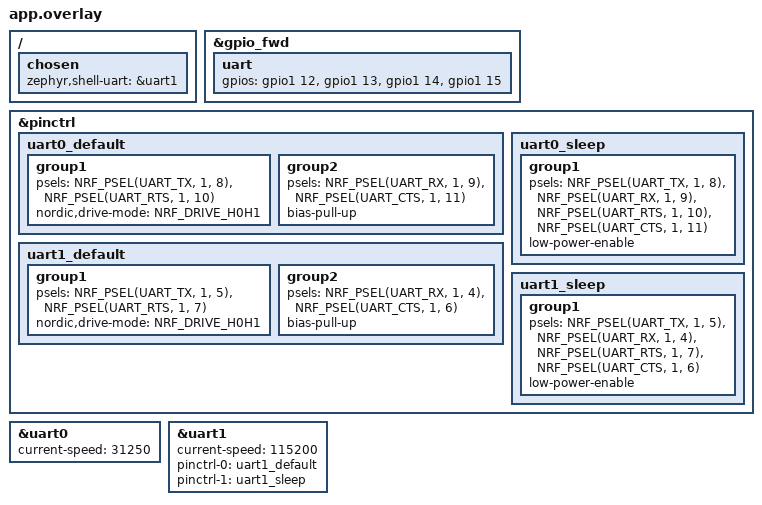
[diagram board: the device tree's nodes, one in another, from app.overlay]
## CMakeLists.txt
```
# SPDX-License-Identifier: Apache-2.0

cmake_minimum_required(VERSION 3.20.0)

# ============================================================================
# Firmware Version Configuration
# ============================================================================
# Update FIRMWARE_VERSION_MINOR for each build/change to track versions
set(FIRMWARE_VERSION_MAJOR 1)
set(FIRMWARE_VERSION_MINOR 3)
set(FIRMWARE_VERSION_PATCH 1)
set(FIRMWARE_VERSION "${FIRMWARE_VERSION_MAJOR}.${FIRMWARE_VERSION_MINOR}.${FIRMWARE_VERSION_PATCH}")

# Force use of nRF SDK Python - check multiple sources
if(DEFINED WEST_PYTHON)
  set(Python3_EXECUTABLE "${WEST_PYTHON}" CACHE FILEPATH "Python executable" FORCE)
elseif(DEFINED ENV{WEST_PYTHON})
  set(Python3_EXECUTABLE "$ENV{WEST_PYTHON}" CACHE FILEPATH "Python executable" FORCE)
elseif(EXISTS "/opt/nordic/ncs/toolchains/322ac893fe/opt/python@3.12/bin/python3.12")
  # Fallback to known SDK Python location
  set(Python3_EXECUTABLE "/opt/nordic/ncs/toolchains/322ac893fe/opt/python@3.12/bin/python3.12" CACHE FILEPATH "Python executable" FORCE)
endif()

find_package(Zephyr REQUIRED HINTS $ENV{ZEPHYR_BASE})
project(guitaracc_basestation)

# ============================================================================
# Generate version header file
# ============================================================================
set(VERSION_HEADER_DIR "${CMAKE_CURRENT_BINARY_DIR}/include")
set(VERSION_HEADER "${VERSION_HEADER_DIR}/firmware_version.h")

# Create include directory
file(MAKE_DIRECTORY "${VERSION_HEADER_DIR}")

# Generate version header
configure_file(
    "${CMAKE_CURRENT_SOURCE_DIR}/src/firmware_version.h.in"
    "${VERSION_HEADER}"
    @ONLY
)

# Add generated include directory to build
target_include_directories(app PRIVATE "${VERSION_HEADER_DIR}")

# Display version during build
message(STATUS "GuitarAcc Basestation Firmware Version: ${FIRMWARE_VERSION}")

# ============================================================================
# Source files
# ============================================================================
target_sources(app PRIVATE 
    src/main.c
    src/midi_logic.c
    src/accel_mapping.c
    src/ui_led.c
    src/ui_interface_shell.c
    src/config_storage.c
)
```

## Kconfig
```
# Copyright (c) 2026 GuitarAcc Project
# SPDX-License-Identifier: Apache-2.0

menu "GuitarAcc Configuration"

config CONFIG_ALLOW_DEFAULT_WRITE
	bool "Allow writing to factory DEFAULT configuration area"
	default n
	help
	  Enable this option to allow writing factory default configuration
	  to the DEFAULT area in QSPI flash. This should only be enabled
	  during development and manufacturing setup.
	  
	  WARNING: This must be disabled for production builds to prevent
	  accidental overwrite of factory defaults.

endmenu

source "Kconfig.zephyr"
```

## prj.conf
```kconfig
# Bluetooth configuration
CONFIG_BT=y
CONFIG_BT_CENTRAL=y
CONFIG_BT_DEVICE_NAME="GuitarAcc Base"
CONFIG_BT_MAX_CONN=4
CONFIG_BT_MAX_PAIRED=4
CONFIG_BT_GATT_CLIENT=y
CONFIG_BT_SMP=y
CONFIG_BT_GATT_DM=y
CONFIG_BT_HOGP=y

# Scan library configuration
CONFIG_BT_SCAN=y
CONFIG_BT_SCAN_FILTER_ENABLE=y
CONFIG_BT_SCAN_UUID_CNT=1

# Settings for bonding
CONFIG_BT_SETTINGS=y
CONFIG_FLASH=y
CONFIG_FLASH_PAGE_LAYOUT=y
CONFIG_FLASH_MAP=y
CONFIG_SETTINGS=y
CONFIG_SETTINGS_NVS=y
CONFIG_NVS=y
CONFIG_NVS_LOG_LEVEL_DBG=y

# Flash driver for configuration storage
CONFIG_MPU_ALLOW_FLASH_WRITE=y

# Crypto for hash validation (using PSA Crypto API for nRF Connect SDK)
CONFIG_NRF_SECURITY=y
CONFIG_NORDIC_SECURITY_BACKEND=y
CONFIG_PSA_CRYPTO_DRIVER_OBERON=y
CONFIG_MBEDTLS_PSA_CRYPTO_C=y
CONFIG_MBEDTLS_SHA256_C=y
CONFIG_PSA_WANT_ALG_SHA_256=y

# Configuration storage options
# Enable this to allow writing factory defaults during development
# WARNING: Disable for production builds!
CONFIG_CONFIG_ALLOW_DEFAULT_WRITE=y

CONFIG_DK_LIBRARY=y
# Stack sizes
CONFIG_MAIN_STACK_SIZE=4096
CONFIG_SYSTEM_WORKQUEUE_STACK_SIZE=2048
CONFIG_HEAP_MEM_POOL_SIZE=2048

# UART for MIDI output
CONFIG_SERIAL=y
CONFIG_UART_INTERRUPT_DRIVEN=y
CONFIG_UART_LINE_CTRL=y

# GPIO for RGB LED control
CONFIG_GPIO=y

# Logging - RTT only, not on console/UART
CONFIG_LOG=y
CONFIG_LOG_PRINTK=n

# Shell (command line interface)
CONFIG_SHELL=y
CONFIG_SHELL_BACKEND_SERIAL=y
CONFIG_SHELL_PROMPT_UART="GuitarAcc:~$ "
CONFIG_SHELL_CMD_BUFF_SIZE=256
CONFIG_SHELL_PRINTF_BUFF_SIZE=512
CONFIG_SHELL_HISTORY=y
CONFIG_SHELL_HISTORY_BUFFER=512
CONFIG_SHELL_TAB=y
CONFIG_SHELL_TAB_AUTOCOMPLETION=y
CONFIG_SHELL_VT100_COLORS=y
CONFIG_SHELL_METAKEYS=y
CONFIG_SHELL_LOG_BACKEND=n

# Enable floating-point printf support for shell
CONFIG_CBPRINTF_FP_SUPPORT=y

# JSON support for config import/export
CONFIG_JSON_LIBRARY=y

# Console backend for shell only (no logging)
CONFIG_CONSOLE=y
CONFIG_UART_CONSOLE=y
CONFIG_CONSOLE_HANDLER=n

CONFIG_DEBUG_THREAD_INFO=y

# RTT (SEGGER Real-Time Transfer) for debug logging only
# RTT is used for ALL logging, UART is ONLY for shell
# TODO: Disable RTT before production shipment for performance/security
CONFIG_USE_SEGGER_RTT=y
CONFIG_RTT_CONSOLE=n
CONFIG_LOG_BACKEND_RTT=y
CONFIG_LOG_BACKEND_UART=n
CONFIG_LOG_BACKEND_SHOW_COLOR=n
CONFIG_LOG_BACKEND_FORMAT_TIMESTAMP=y
```

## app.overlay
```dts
/* UART configuration for MIDI output */

/* Chosen devices */
/ {
	chosen {
		zephyr,shell-uart = &uart1;
	};
};

/* Reconfigure GPIO forwarder to forward P1.12, P1.13, P1.14, P1.15 to network core */
&gpio_fwd {
	status = "okay";
	uart {
		gpios = <&gpio1 12 0>, <&gpio1 13 0>, <&gpio1 14 0>, <&gpio1 15 0>;
	};
};

/* Override UART0 pinctrl - TX and RX swapped: TX=P1.8, RX=P1.9, RTS=P1.10, CTS=P1.11 */
&pinctrl {
	uart0_default: uart0_default {
		group1 {
			psels = <NRF_PSEL(UART_TX, 1, 8)>,
				<NRF_PSEL(UART_RTS, 1, 10)>;
			nordic,drive-mode = <NRF_DRIVE_H0H1>;  /* High drive both LOW and HIGH (~5mA) */
		};
		group2 {
			psels = <NRF_PSEL(UART_RX, 1, 9)>,
				<NRF_PSEL(UART_CTS, 1, 11)>;
			bias-pull-up;
		};
	};

	uart0_sleep: uart0_sleep {
		group1 {
			psels = <NRF_PSEL(UART_TX, 1, 8)>,
				<NRF_PSEL(UART_RX, 1, 9)>,
				<NRF_PSEL(UART_RTS, 1, 10)>,
				<NRF_PSEL(UART_CTS, 1, 11)>;
			low-power-enable;
		};
	};
};

&uart0 {
	status = "okay";
	current-speed = <31250>;  /* MIDI baud rate */
};

/* Enable UART1 on VCOM0 pins for UI/Config interface */
&pinctrl {
	uart1_default: uart1_default {
		group1 {
			psels = <NRF_PSEL(UART_TX, 1, 5)>,
				<NRF_PSEL(UART_RTS, 1, 7)>;
			nordic,drive-mode = <NRF_DRIVE_H0H1>;
		};
		group2 {
			psels = <NRF_PSEL(UART_RX, 1, 4)>,
				<NRF_PSEL(UART_CTS, 1, 6)>;
			bias-pull-up;
		};
	};

	uart1_sleep: uart1_sleep {
		group1 {
			psels = <NRF_PSEL(UART_TX, 1, 5)>,
				<NRF_PSEL(UART_RX, 1, 4)>,
				<NRF_PSEL(UART_RTS, 1, 7)>,
				<NRF_PSEL(UART_CTS, 1, 6)>;
			low-power-enable;
		};
	};
};

&uart1 {
	status = "okay";
	current-speed = <115200>;  /* Standard VCOM baud rate */
	pinctrl-0 = <&uart1_default>;
	pinctrl-1 = <&uart1_sleep>;
	pinctrl-names = "default", "sleep";
};
```

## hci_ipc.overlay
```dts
/* Network core UART0 configuration - swapped to use P1.5, P1.4, P1.7, P1.6 */

&pinctrl {
	uart0_default: uart0_default {
		group1 {
			psels = <NRF_PSEL(UART_TX, 1, 5)>,
				<NRF_PSEL(UART_RTS, 1, 7)>;
		};
		group2 {
			psels = <NRF_PSEL(UART_RX, 1, 4)>,
				<NRF_PSEL(UART_CTS, 1, 6)>;
			bias-pull-up;
		};
	};

	uart0_sleep: uart0_sleep {
		group1 {
			psels = <NRF_PSEL(UART_TX, 1, 5)>,
				<NRF_PSEL(UART_RX, 1, 4)>,
				<NRF_PSEL(UART_RTS, 1, 7)>,
				<NRF_PSEL(UART_CTS, 1, 6)>;
			low-power-enable;
		};
	};
};
```

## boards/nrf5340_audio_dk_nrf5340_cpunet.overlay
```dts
/* Network core UART0 configuration - using P1.12-P1.15 */

&pinctrl {
	uart0_default: uart0_default {
		group1 {
			psels = <NRF_PSEL(UART_TX, 1, 12)>,
				<NRF_PSEL(UART_RTS, 1, 14)>;
		};
		group2 {
			psels = <NRF_PSEL(UART_RX, 1, 13)>,
				<NRF_PSEL(UART_CTS, 1, 15)>;
			bias-pull-up;
		};
	};

	uart0_sleep: uart0_sleep {
		group1 {
			psels = <NRF_PSEL(UART_TX, 1, 12)>,
				<NRF_PSEL(UART_RX, 1, 13)>,
				<NRF_PSEL(UART_RTS, 1, 14)>,
				<NRF_PSEL(UART_CTS, 1, 15)>;
			low-power-enable;
		};
	};
};
```

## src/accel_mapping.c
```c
/*
 * Accelerometer Rotation Pipeline
 * 3D rotation, normalization, and configurable conversion to MIDI
 * 
 * Copyright (c) 2026 GuitarAcc Project
 * SPDX-License-Identifier: Apache-2.0
 */

#include "accel_mapping.h"
#include <stddef.h>
#include <string.h>

#ifndef M_PI
#define M_PI 3.14159265358979323846
#endif

/* Fixed input points for lookup table interpolation */
static const float lookup_input_points[LOOKUP_TABLE_POINTS] = {
	-1.0f, -0.5f, 0.0f, 0.5f, 1.0f
};

/* Helper to clamp float to range */
static inline float clampf(float value, float min, float max)
{
	if (value < min) return min;
	if (value > max) return max;
	return value;
}

/* Helper to clamp to MIDI range */
static inline uint8_t clamp_midi(int32_t value)
{
	if (value < MIDI_MIN_VALUE) return MIDI_MIN_VALUE;
	if (value > MIDI_MAX_VALUE) return MIDI_MAX_VALUE;
	return (uint8_t)value;
}

/* Convert degrees to radians */
static inline float deg_to_rad(float degrees)
{
	return degrees * M_PI / 180.0f;
}

void accel_rotation_init_defaults(struct accel_rotation_config *config)
{
	if (config == NULL) {
		return;
	}
	
	memset(config, 0, sizeof(*config));
	config->rho_angle = 0.0f;
	config->theta_angle = 0.0f;
	config->midi_cc = 1;  /* Default to CC 1 (modulation wheel) */
	config->func_type = CONV_FUNC_LINEAR;
	config->params.linear.scale = 1.0f;
	config->params.linear.offset = 0.0f;
}

void apply_rotation(struct vector3d *vec, float rho_deg, float theta_deg)
{
	if (vec == NULL) {
		return;
	}
	
	float rho_rad = deg_to_rad(rho_deg);
	float theta_rad = deg_to_rad(theta_deg);
	
	float cos_rho = cosf(rho_rad);
	float sin_rho = sinf(rho_rad);
	float cos_theta = cosf(theta_rad);
	float sin_theta = sinf(theta_rad);
	
	/* Rotation around X axis (rho) */
	float y1 = vec->y * cos_rho - vec->z * sin_rho;
	float z1 = vec->y * sin_rho + vec->z * cos_rho;
	vec->y = y1;
	vec->z = z1;
	
	/* Rotation around Y axis (theta) */
	float x2 = vec->x * cos_theta + vec->z * sin_theta;
	float z2 = -vec->x * sin_theta + vec->z * cos_theta;
	vec->x = x2;
	vec->z = z2;
}

bool normalize_vector(struct vector3d *vec)
{
	if (vec == NULL) {
		return false;
	}
	
	float magnitude = sqrtf(vec->x * vec->x + vec->y * vec->y + vec->z * vec->z);
	
	/* Avoid division by zero */
	if (magnitude < 1e-6f) {
		return false;
	}
	
	vec->x /= magnitude;
	vec->y /= magnitude;
	vec->z /= magnitude;
	
	return true;
}

uint8_t scalar_to_midi(float scalar, enum conversion_func_type func_type,
                       const union conversion_params *params)
{
	if (params == NULL) {
		return MIDI_MIN_VALUE;
	}
	
	float result = 0.0f;
	
	/* Clamp input scalar to valid range */
	scalar = clampf(scalar, -1.0f, 1.0f);
	
	switch (func_type) {
	case CONV_FUNC_LINEAR: {
		/* Linear: MIDI = clamp((scalar * scale + offset) * 127, 0, 127) */
		result = (scalar * params->linear.scale + params->linear.offset) * 127.0f;
		break;
	}
	
	case CONV_FUNC_EXPONENTIAL: {
		/* Exponential: MIDI = clamp(((scalar + 1)/2)^exponent * 127, 0, 127) */
		float normalized = (scalar + 1.0f) / 2.0f;  /* Map to [0, 1] */
		result = powf(normalized, params->exponential.exponent) * 127.0f;
		break;
	}
	
	case CONV_FUNC_SCURVE: {
		/* S-Curve: MIDI = clamp(127 / (1 + e^(-steepness * scalar)), 0, 127) */
		float exp_val = expf(-params->scurve.steepness * scalar);
		result = 127.0f / (1.0f + exp_val);
		break;
	}
	
	case CONV_FUNC_LOOKUP: {
		/* Lookup table with linear interpolation */
		/* Find the two surrounding points */
		int idx = 0;
		for (int i = 0; i < LOOKUP_TABLE_POINTS - 1; i++) {
			if (scalar >= lookup_input_points[i] && scalar <= lookup_input_points[i + 1]) {
				idx = i;
				break;
			}
		}
		
		/* Handle edge case: scalar exactly at last point */
		if (scalar >= lookup_input_points[LOOKUP_TABLE_POINTS - 1]) {
			return params->lookup.values[LOOKUP_TABLE_POINTS - 1];
		}
		
		/* Linear interpolation between two points */
		float x0 = lookup_input_points[idx];
		float x1 = lookup_input_points[idx + 1];
		float y0 = (float)params->lookup.values[idx];
		float y1 = (float)params->lookup.values[idx + 1];
		
		float t = (scalar - x0) / (x1 - x0);
		result = y0 + t * (y1 - y0);
		break;
	}
	
	default:
		/* Unknown function type, return mid-range */
		return 64;
	}
	
	/* Clamp to MIDI range and return */
	return clamp_midi((int32_t)(result + 0.5f));  /* Round to nearest */
}

bool validate_rotation_config(struct accel_rotation_config *config)
{
	if (config == NULL) {
		return false;
	}
	
	bool valid = true;
	
	/* Validate angles (wrap to 0-360) */
	while (config->rho_angle < 0.0f) {
		config->rho_angle += 360.0f;
		valid = false;
	}
	while (config->rho_angle >= 360.0f) {
		config->rho_angle -= 360.0f;
		valid = false;
	}
	
	while (config->theta_angle < 0.0f) {
		config->theta_angle += 360.0f;
		valid = false;
	}
	while (config->theta_angle >= 360.0f) {
		config->theta_angle -= 360.0f;
		valid = false;
	}
	
	/* Validate MIDI CC (clamp to 0-127) */
	if (config->midi_cc > 127) {
		config->midi_cc = 127;
		valid = false;
	}
	
	/* Validate function type */
	if (config->func_type > CONV_FUNC_LOOKUP) {
		config->func_type = CONV_FUNC_LINEAR;
		valid = false;
	}
	
	/* Validate function parameters */
	switch (config->func_type) {
	case CONV_FUNC_LINEAR:
		/* Scale: -10.0 to -0.1 or 0.1 to 10.0 (exclude near-zero values) */
		if (config->params.linear.scale >= -0.1f && config->params.linear.scale <= 0.1f) {
			/* Too close to zero, snap to minimum magnitude */
			config->params.linear.scale = (config->params.linear.scale >= 0.0f) ? 0.1f : -0.1f;
			valid = false;
		} else if (config->params.linear.scale < -10.0f) {
			config->params.linear.scale = -10.0f;
			valid = false;
		} else if (config->params.linear.scale > 10.0f) {
			config->params.linear.scale = 10.0f;
			valid = false;
		}
		if (config->params.linear.offset < -1.0f || config->params.linear.offset > 1.0f) {
			config->params.linear.offset = clampf(config->params.linear.offset, -1.0f, 1.0f);
			valid = false;
		}
		break;
		
	case CONV_FUNC_EXPONENTIAL:
		if (config->params.exponential.exponent < 0.1f || 
		    config->params.exponential.exponent > 5.0f) {
			config->params.exponential.exponent = 
				clampf(config->params.exponential.exponent, 0.1f, 5.0f);
			valid = false;
		}
		break;
		
	case CONV_FUNC_SCURVE:
		if (config->params.scurve.steepness < 1.0f || 
		    config->params.scurve.steepness > 20.0f) {
			config->params.scurve.steepness = 
				clampf(config->params.scurve.steepness, 1.0f, 20.0f);
			valid = false;
		}
		break;
		
	case CONV_FUNC_LOOKUP:
		/* Validate all lookup table values are in MIDI range */
		for (int i = 0; i < LOOKUP_TABLE_POINTS; i++) {
			if (config->params.lookup.values[i] > 127) {
				config->params.lookup.values[i] = 127;
				valid = false;
			}
		}
		break;
	}
	
	return valid;
}

uint8_t accel_rotation_pipeline(const struct accel_rotation_config *config,
                                 int16_t accel_x, int16_t accel_y, int16_t accel_z,
                                 uint8_t *midi_cc_out)
{
	if (config == NULL) {
		if (midi_cc_out != NULL) {
			*midi_cc_out = 1;  /* Default CC */
		}
		return MIDI_MIN_VALUE;
	}
	
	/* Stage 1: Convert milli-g to g and create vector */
	struct vector3d vec = {
		.x = (float)accel_x / 1000.0f,
		.y = (float)accel_y / 1000.0f,
		.z = (float)accel_z / 1000.0f
	};
	
	/* Stage 2: Apply angular rotation */
	apply_rotation(&vec, config->rho_angle, config->theta_angle);
	
	/* Stage 3: Normalize to unit vector */
	if (!normalize_vector(&vec)) {
		/* If normalization fails (zero vector), return mid-range */
		if (midi_cc_out != NULL) {
			*midi_cc_out = config->midi_cc;
		}
		return 64;
	}
	
	/* Stage 4: Project to 1D (X-axis component) */
	float scalar = vec.x;  /* Already in range [-1.0, 1.0] after normalization */
	
	/* Stage 5: Convert scalar to MIDI */
	uint8_t midi_value = scalar_to_midi(scalar, config->func_type, &config->params);
	
	/* Output the MIDI CC number */
	if (midi_cc_out != NULL) {
		*midi_cc_out = config->midi_cc;
	}
	
	return midi_value;
}

/* =============================================================================
 * Legacy Compatibility Functions (deprecated)
 * ============================================================================= */

uint8_t accel_map_to_midi(const struct accel_mapping_config *config, int16_t accel_value)
{
	if (config == NULL) {
		return MIDI_MIN_VALUE;
	}
	
	/* Handle edge case where min == max to avoid division by zero */
	if (config->accel_min == config->accel_max) {
		return MIDI_MIN_VALUE;
	}
	
	/* Calculate the range */
	int32_t accel_range = (int32_t)config->accel_max - (int32_t)config->accel_min;
	int32_t accel_offset = (int32_t)accel_value - (int32_t)config->accel_min;
	
	/* Linear mapping with proper handling of positive and negative ranges */
	int32_t midi_value = (accel_offset * (MIDI_MAX_VALUE - MIDI_MIN_VALUE)) / accel_range;
	midi_value += MIDI_MIN_VALUE;
	
	/* Clamp to valid MIDI range */
	if (midi_value < MIDI_MIN_VALUE) {
		midi_value = MIDI_MIN_VALUE;
	} else if (midi_value > MIDI_MAX_VALUE) {
		midi_value = MIDI_MAX_VALUE;
	}
	
	return (uint8_t)midi_value;
}

void accel_mapping_init_linear(struct accel_mapping_config *config, 
                                int16_t accel_min, 
                                int16_t accel_max)
{
	if (config == NULL) {
		return;
	}
	
	config->accel_min = accel_min;
	config->accel_max = accel_max;
}
```

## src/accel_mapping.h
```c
/*
 * Accelerometer Rotation Pipeline
 * 3D rotation, normalization, and configurable conversion to MIDI
 * 
 * Copyright (c) 2026 GuitarAcc Project
 * SPDX-License-Identifier: Apache-2.0
 */

#ifndef ACCEL_MAPPING_H
#define ACCEL_MAPPING_H

#include <stdint.h>
#include <stdbool.h>
#include <math.h>

/* MIDI value range constants */
#define MIDI_MIN_VALUE 0
#define MIDI_MAX_VALUE 127

/* Number of lookup table points */
#define LOOKUP_TABLE_POINTS 5

/**
 * Conversion function types
 */
enum conversion_func_type {
	CONV_FUNC_LINEAR,      /* Linear scaling with offset */
	CONV_FUNC_EXPONENTIAL, /* Exponential curve */
	CONV_FUNC_SCURVE,      /* S-curve (sigmoid) */
	CONV_FUNC_LOOKUP       /* 5-point lookup table with linear interpolation */
};

/**
 * Conversion function parameters
 * Storage optimized for maximum 5 bytes per configuration
 */
union conversion_params {
	/* Linear: scale and offset */
	struct {
		float scale;   /* -10.0 to -0.1 or 0.1 to 10.0 (negative reverses direction) */
		float offset;  /* -1.0 to 1.0 */
	} linear;
	
	/* Exponential: single exponent parameter */
	struct {
		float exponent; /* 0.1 to 5.0 */
	} exponential;
	
	/* S-curve: steepness parameter */
	struct {
		float steepness; /* 1.0 to 20.0 */
	} scurve;
	
	/* Lookup table: 5 output values at fixed input points */
	struct {
		uint8_t values[LOOKUP_TABLE_POINTS]; /* Output MIDI values 0-127 */
		/* Fixed input points: -1.0, -0.5, 0.0, 0.5, 1.0 */
	} lookup;
};

/**
 * Accelerometer rotation pipeline configuration
 * Total storage: 15 bytes maximum
 */
struct accel_rotation_config {
	float rho_angle;     /* Rotation around X axis (degrees, 0-360) - 4 bytes */
	float theta_angle;   /* Rotation around Y axis (degrees, 0-360) - 4 bytes */
	uint8_t midi_cc;     /* MIDI CC number (0-127) - 1 byte */
	enum conversion_func_type func_type;  /* Conversion function type - 1 byte */
	union conversion_params params;       /* Function parameters - 5 bytes max */
};

/**
 * 3D vector for accelerometer data
 */
struct vector3d {
	float x;
	float y;
	float z;
};

/**
 * Initialize rotation pipeline configuration with defaults
 * Defaults: rho=0, theta=0, CC=1, linear function (scale=1.0, offset=0.0)
 * 
 * @param config Pointer to configuration structure to initialize
 */
void accel_rotation_init_defaults(struct accel_rotation_config *config);

/**
 * Process accelerometer data through rotation pipeline
 * 
 * Pipeline stages:
 * 1. Angular rotation (X and Y axis)
 * 2. Unit vector normalization
 * 3. 1D projection (X-axis)
 * 4. Scalar to MIDI conversion
 * 
 * @param config Pipeline configuration
 * @param accel_x X-axis acceleration (milli-g)
 * @param accel_y Y-axis acceleration (milli-g)
 * @param accel_z Z-axis acceleration (milli-g)
 * @param midi_cc_out Output MIDI CC number (from config)
 * @return MIDI value (0-127), clamped to valid range
 */
uint8_t accel_rotation_pipeline(const struct accel_rotation_config *config,
                                 int16_t accel_x, int16_t accel_y, int16_t accel_z,
                                 uint8_t *midi_cc_out);

/**
 * Apply angular rotation to 3D vector
 * Rotates around X axis (rho), then Y axis (theta)
 * 
 * @param vec Input/output vector
 * @param rho_deg Rotation around X axis (degrees)
 * @param theta_deg Rotation around Y axis (degrees)
 */
void apply_rotation(struct vector3d *vec, float rho_deg, float theta_deg);

/**
 * Normalize vector to unit length
 * 
 * @param vec Input/output vector
 * @return true if normalization successful, false if vector is zero
 */
bool normalize_vector(struct vector3d *vec);

/**
 * Convert scalar value to MIDI using configured conversion function
 * 
 * @param scalar Input scalar value (-1.0 to 1.0)
 * @param func_type Conversion function type
 * @param params Function parameters
 * @return MIDI value (0-127), clamped to valid range
 */
uint8_t scalar_to_midi(float scalar, enum conversion_func_type func_type,
                       const union conversion_params *params);

/**
 * Validate and sanitize pipeline configuration parameters
 * Invalid parameters are corrected to safe defaults
 * 
 * @param config Configuration to validate
 * @return true if configuration was valid, false if corrections were made
 */
bool validate_rotation_config(struct accel_rotation_config *config);

/* Legacy compatibility - deprecated, use rotation pipeline instead */
struct accel_mapping_config {
	int16_t accel_min;
	int16_t accel_max;
};
uint8_t accel_map_to_midi(const struct accel_mapping_config *config, int16_t accel_value);
void accel_mapping_init_linear(struct accel_mapping_config *config, 
                                int16_t accel_min, int16_t accel_max);

#endif /* ACCEL_MAPPING_H */
```

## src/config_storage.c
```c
/*
 * Copyright (c) 2026 GuitarAcc Project
 * SPDX-License-Identifier: Apache-2.0
 */

#include "config_storage.h"
#include <zephyr/kernel.h>
#include <zephyr/device.h>
#include <zephyr/drivers/flash.h>
#include <zephyr/logging/log.h>
#include <zephyr/sys/crc.h>
#include <string.h>

#if defined(CONFIG_MBEDTLS_SHA256_C)
#include <mbedtls/sha256.h>
#endif

LOG_MODULE_REGISTER(config_storage, LOG_LEVEL_DBG);

/* Magic number for configuration header */
#define CONFIG_MAGIC 0x47544143  /* "GTAC" */

/* Internal flash device (nRF5340 has 1MB internal flash) */
#define FLASH_DEVICE DEVICE_DT_GET(DT_CHOSEN(zephyr_flash_controller))

/* Memory layout in internal flash using Partition Manager
 * The settings_storage partition is 8KB at 0xFC000-0xFDFFF
 * This matches the partition manager output and avoids code conflicts
 */
#define CONFIG_FLASH_OFFSET  0x000FC000  /* From partition manager */
#define CONFIG_STORAGE_SIZE  0x00002000  /* 8KB (actual partition size) */

/* Ping-pong storage with two 4KB areas (no DEFAULT area) */
#define CONFIG_AREA_A_OFFSET   (CONFIG_FLASH_OFFSET + 0x0000)  /* +0KB */
#define CONFIG_AREA_A_SIZE     0x00001000  /* 4KB */
#define CONFIG_AREA_B_OFFSET   (CONFIG_FLASH_OFFSET + 0x1000)  /* +4KB */
#define CONFIG_AREA_B_SIZE     0x00001000  /* 4KB */

/* Flash page size for nRF5340 internal flash */
#define FLASH_PAGE_SIZE 4096

/* Current configuration state */
static struct config_data current_config;
static enum config_area active_area = CONFIG_AREA_A;
static uint32_t current_sequence = 0;
static bool initialized = false;

/* Runtime flag to enable DEFAULT area writes (double protection) */
static bool default_write_unlocked = false;

/* Flash device handle */
static const struct device *flash_dev;

/**
 * @brief Calculate SHA256 hash of data
 */
static int calculate_hash(const void *data, size_t len, uint8_t *hash)
{
#if defined(CONFIG_MBEDTLS_SHA256_C)
	mbedtls_sha256_context ctx;
	
	mbedtls_sha256_init(&ctx);
	int ret = mbedtls_sha256_starts(&ctx, 0); /* 0 = SHA256, not SHA224 */
	if (ret != 0) {
		mbedtls_sha256_free(&ctx);
		return -EIO;
	}
	
	ret = mbedtls_sha256_update(&ctx, data, len);
	if (ret != 0) {
		mbedtls_sha256_free(&ctx);
		return -EIO;
	}
	
	ret = mbedtls_sha256_finish(&ctx, hash);
	mbedtls_sha256_free(&ctx);
	
	return (ret == 0) ? 0 : -EIO;
#else
	LOG_ERR("SHA256 not available, using simple checksum");
	/* Fallback: simple checksum (not cryptographically secure) */
	uint32_t sum = 0;
	const uint8_t *bytes = (const uint8_t *)data;
	for (size_t i = 0; i < len; i++) {
		sum += bytes[i];
	}
	memset(hash, 0, CONFIG_HASH_SIZE);
	memcpy(hash, &sum, sizeof(sum));
	return 0;
#endif
}

/**
 * @brief Verify hash of data
 */
static bool verify_hash(const void *data, size_t len, const uint8_t *expected_hash)
{
	uint8_t calculated_hash[CONFIG_HASH_SIZE];
	
	if (calculate_hash(data, len, calculated_hash) != 0) {
		return false;
	}
	
	return memcmp(calculated_hash, expected_hash, CONFIG_HASH_SIZE) == 0;
}

/**
 * @brief Calculate CRC32 of header (excluding crc32 field)
 */
static uint32_t calculate_header_crc(const struct config_header *header)
{
	size_t crc_len = offsetof(struct config_header, crc32);
	return crc32_ieee((const uint8_t *)header, crc_len);
}

/**
 * @brief Get flash offset for configuration area
 */
static off_t get_area_offset(enum config_area area)
{
	switch (area) {
	case CONFIG_AREA_A:
		return CONFIG_AREA_A_OFFSET;
	case CONFIG_AREA_B:
		return CONFIG_AREA_B_OFFSET;
	default:
		return -EINVAL;
	}
}

/**
 * @brief Read configuration area from flash
 */
static int read_area(enum config_area area, struct config_header *header,
		     struct config_data *data)
{
	off_t offset = get_area_offset(area);
	if (offset < 0) {
		return offset;
	}
	
	/* Read header */
	int ret = flash_read(flash_dev, offset, header, sizeof(*header));
	if (ret != 0) {
		LOG_ERR("Failed to read header from area %d: %d", area, ret);
		return ret;
	}
	
	/* Validate magic number */
	if (header->magic != CONFIG_MAGIC) {
		LOG_WRN("Invalid magic in area %d: 0x%08x", area, header->magic);
		return -EINVAL;
	}
	
	/* Validate header CRC */
	uint32_t calculated_crc = calculate_header_crc(header);
	if (calculated_crc != header->crc32) {
		LOG_WRN("Header CRC mismatch in area %d", area);
		return -EINVAL;
	}
	
	/* Validate data size */
	if (header->data_size > CONFIG_DATA_MAX_SIZE) {
		LOG_ERR("Invalid data size in area %d: %u", area, header->data_size);
		return -EINVAL;
	}
	
	/* Read data */
	ret = flash_read(flash_dev, offset + sizeof(*header), data,
			 sizeof(*data));
	if (ret != 0) {
		LOG_ERR("Failed to read data from area %d: %d", area, ret);
		return ret;
	}
	
	/* Verify data hash */
	if (!verify_hash(data, sizeof(*data), header->hash)) {
		LOG_ERR("Data hash mismatch in area %d", area);
		return -EINVAL;
	}
	
	LOG_INF("Successfully read area %d (seq=%u)", area, header->sequence);
	return 0;
}

/**
 * @brief Write configuration area to flash
 */
static int write_area(enum config_area area, const struct config_data *data,
		      uint32_t sequence)
{
	off_t offset = get_area_offset(area);
	if (offset < 0) {
		return offset;
	}
	
	/* Build header */
	struct config_header header = {
		.magic = CONFIG_MAGIC,
		.version = CONFIG_VERSION,
		.sequence = sequence,
		.data_size = sizeof(*data),
	};
	
	/* Calculate data hash */
	int ret = calculate_hash(data, sizeof(*data), header.hash);
	if (ret != 0) {
		LOG_ERR("Failed to calculate hash: %d", ret);
		return ret;
	}
	
	/* Calculate header CRC */
	header.crc32 = calculate_header_crc(&header);
	
	/* Erase flash page */
	LOG_DBG("Erasing flash at offset 0x%08lx, size 0x%x", (long)offset, FLASH_PAGE_SIZE);
	ret = flash_erase(flash_dev, offset, FLASH_PAGE_SIZE);
	if (ret != 0) {
		LOG_ERR("Failed to erase area %d at 0x%08lx: %d", area, (long)offset, ret);
		return ret;
	}
	
	/* Write header */
	LOG_DBG("Writing header to offset 0x%08lx", (long)offset);
	ret = flash_write(flash_dev, offset, &header, sizeof(header));
	if (ret != 0) {
		LOG_ERR("Failed to write header to area %d at 0x%08lx: %d", area, (long)offset, ret);
		return ret;
	}
	
	/* Write data */
	LOG_DBG("Writing data to offset 0x%08lx", (long)(offset + sizeof(header)));
	ret = flash_write(flash_dev, offset + sizeof(header), data, sizeof(*data));
	if (ret != 0) {
		LOG_ERR("Failed to write data to area %d at 0x%08lx: %d", area, (long)(offset + sizeof(header)), ret);
		return ret;
	}
	
	LOG_INF("Successfully wrote area %d (seq=%u)", area, sequence);
	return 0;
}

void config_storage_get_hardcoded_defaults(struct config_data *data)
{
	memset(data, 0, sizeof(*data));
	
	/* Global defaults */
	data->global.default_patch = 0;  /* Default to patch 0 */
	data->global.midi_channel = 0;  /* Channel 1 (0-indexed) */
	data->global.max_guitars = 4;
	data->global.scan_interval_ms = 100;
	data->global.led_brightness = 128;  /* 50% brightness */
	for (int i = 0; i < 3; i++) {
		data->global.accel_scale[i] = 206;  /* ±0.2g full scale (±206mg maps to MIDI 0-127) */
		data->global.accel_offset[i] = 289;   /* Center point (289mg) */
	}
	data->global.running_average_enable = 1;  /* Enabled */
	data->global.running_average_depth = 5;   /* 5 samples */
	
	/* Initialize all patches with defaults */
	for (int p = 0; p < 16; p++) {
		data->patches[p].velocity_curve = 0; /* Linear */

		data->patches[p].cc_mapping[0] = 16;  /* CC16: General Purpose 1 (X-axis) */
		data->patches[p].cc_mapping[1] = 17;  /* CC17: General Purpose 2 (Y-axis) */
		data->patches[p].cc_mapping[2] = 18;  /* CC18: General Purpose 3 (Z-axis) */
		data->patches[p].cc_mapping[3] = 19;  /* CC19: General Purpose 4 (Roll) */
		data->patches[p].cc_mapping[4] = 20;  /* CC20: General Purpose 5 (Pitch) */
		data->patches[p].cc_mapping[5] = 21;  /* CC21: General Purpose 6 (Yaw) */

		data->patches[p].accel_min[0] = 0;  /* CC16: Min value (X-axis) */
		data->patches[p].accel_min[1] = 0;  /* CC17: Min value (Y-axis) */
		data->patches[p].accel_min[2] = 0;  /* CC18: Min value (Z-axis) */
		data->patches[p].accel_min[3] = 0;  /* CC19: Min value (Roll) */
		data->patches[p].accel_min[4] = 0;  /* CC20: Min value (Pitch) */
		data->patches[p].accel_min[5] = 0;  /* CC21: Min value (Yaw) */

		data->patches[p].accel_max[0] = 127;  /* CC16: Max value (X-axis) */
		data->patches[p].accel_max[1] = 127;  /* CC17: Max value (Y-axis) */
		data->patches[p].accel_max[2] = 127;  /* CC18: Max value (Z-axis) */
		data->patches[p].accel_max[3] = 127;  /* CC19: Max value (Roll) */
		data->patches[p].accel_max[4] = 127;  /* CC20: Max value (Pitch) */
		data->patches[p].accel_max[5] = 127;  /* CC21: Max value (Yaw) */

		data->patches[p].led_mode = 0;          /* Normal mode */
		data->patches[p].accel_deadzone = 1;  /* MIDI CC change threshold (1 = send on any change) */
		snprintf(data->patches[p].patch_name, sizeof(data->patches[p].patch_name), 
		         "Patch %d", p);
		
		/* Initialize rotation pipeline with defaults */
		accel_rotation_init_defaults(&data->patches[p].rotation_pipeline);
	}
}

int config_storage_init(void)
{
	if (initialized) {
		return 0;
	}
	
	/* Get flash device */
	flash_dev = FLASH_DEVICE;
	if (!device_is_ready(flash_dev)) {
		LOG_ERR("Internal flash device not ready");
		return -ENODEV;
	}
	
	LOG_INF("Internal flash device ready");
	
	/* Check flash parameters */
	const struct flash_parameters *params = flash_get_parameters(flash_dev);
	LOG_INF("Flash write block size: %zu bytes", params->write_block_size);
	LOG_INF("Flash erase value: 0x%02x", params->erase_value);
	
	size_t page_count = flash_get_page_count(flash_dev);
	LOG_INF("Flash page count: %zu", page_count);
	
	/* Verify our structures are aligned */
	LOG_INF("Header size: %zu bytes", sizeof(struct config_header));
	LOG_INF("Data size: %zu bytes", sizeof(struct config_data));
	
	/* Log storage partition info */
	LOG_INF("Storage: offset=0x%08x size=0x%x", CONFIG_FLASH_OFFSET, CONFIG_STORAGE_SIZE);
	LOG_INF("A: 0x%08x, B: 0x%08x", CONFIG_AREA_A_OFFSET, CONFIG_AREA_B_OFFSET);
	
	/* Try to read from both active areas */
	static struct config_header header_a, header_b;
	static struct config_data data_a, data_b;
	
	int ret_a = read_area(CONFIG_AREA_A, &header_a, &data_a);
	int ret_b = read_area(CONFIG_AREA_B, &header_b, &data_b);
	
	/* Determine which area to use based on sequence numbers */
	if (ret_a == 0 && ret_b == 0) {
		/* Both valid - use the one with higher sequence */
		if (header_a.sequence > header_b.sequence) {
			active_area = CONFIG_AREA_A;
			current_sequence = header_a.sequence;
			memcpy(&current_config, &data_a, sizeof(current_config));
			LOG_INF("Using area A (seq=%u)", current_sequence);
		} else {
			active_area = CONFIG_AREA_B;
			current_sequence = header_b.sequence;
			memcpy(&current_config, &data_b, sizeof(current_config));
			LOG_INF("Using area B (seq=%u)", current_sequence);
		}
	} else if (ret_a == 0) {
		/* Only A is valid */
		active_area = CONFIG_AREA_A;
		current_sequence = header_a.sequence;
		memcpy(&current_config, &data_a, sizeof(current_config));
		LOG_INF("Using area A (seq=%u, B invalid)", current_sequence);
	} else if (ret_b == 0) {
		/* Only B is valid */
		active_area = CONFIG_AREA_B;
		current_sequence = header_b.sequence;
		memcpy(&current_config, &data_b, sizeof(current_config));
		LOG_INF("Using area B (seq=%u, A invalid)", current_sequence);
	} else {
		/* Neither valid - use hardcoded defaults */
		LOG_WRN("No valid config found, using hardcoded defaults");
		config_storage_get_hardcoded_defaults(&current_config);
		current_sequence = 0;
		active_area = CONFIG_AREA_A;
		
		/* Try to save hardcoded defaults to active area (non-fatal if it fails) */
		int ret = write_area(CONFIG_AREA_A, &current_config, 1);
		if (ret == 0) {
			current_sequence = 1;
			LOG_INF("Hardcoded defaults written to area A");
		} else {
			LOG_WRN("Failed to write defaults to area A: %d (continuing anyway)", ret);
		}
	}
	
	initialized = true;
	LOG_INF("Configuration storage initialized");
	return 0;
}

int config_storage_save(const struct config_data *data)
{
	if (!initialized) {
		LOG_ERR("Save failed: not initialized");
		return -EACCES;
	}
	
	LOG_DBG("Save: current area=%d, seq=%u", active_area, current_sequence);
	
	/* Determine next area (ping-pong) */
	enum config_area next_area = (active_area == CONFIG_AREA_A) ?
				     CONFIG_AREA_B : CONFIG_AREA_A;
	
	LOG_INF("Save: switching from area %d to area %d", active_area, next_area);
	
	/* Increment sequence number */
	uint32_t next_sequence = current_sequence + 1;
	
	LOG_DBG("Save: next_sequence=%u", next_sequence);
	
	/* Write to inactive area */
	int ret = write_area(next_area, data, next_sequence);
	if (ret != 0) {
		LOG_ERR("Save failed: write_area returned %d", ret);
		return ret;
	}
	
	/* Update current state */
	memcpy(&current_config, data, sizeof(current_config));
	active_area = next_area;
	current_sequence = next_sequence;
	
	LOG_INF("Configuration saved to area %d (seq=%u)",
		active_area, current_sequence);
	return 0;
}

int config_storage_load(struct config_data *data)
{
	if (!initialized) {
		return -EACCES;
	}
	
	memcpy(data, &current_config, sizeof(*data));
	return 0;
}

int config_storage_restore_defaults(void)
{
	if (!initialized) {
		return -EACCES;
	}
	
	static struct config_data data;
	
	/* Use hardcoded defaults */
	config_storage_get_hardcoded_defaults(&data);
	LOG_INF("Restoring hardcoded factory defaults");
	
	/* Save to active storage */
	return config_storage_save(&data);
}

int config_storage_get_info(enum config_area *area, uint32_t *sequence)
{
	if (!initialized) {
		return -EACCES;
	}
	
	if (area) {
		*area = active_area;
	}
	if (sequence) {
		*sequence = current_sequence;
	}
	
	return 0;
}

int config_storage_unlock_default_write(void)
{
	if (!initialized) {
		return -EACCES;
	}
	
#ifndef CONFIG_CONFIG_ALLOW_DEFAULT_WRITE
	LOG_ERR("DEFAULT write disabled at compile time");
	return -EPERM;
#endif
	
	LOG_WRN("*** DEFAULT AREA WRITE UNLOCKED ***");
	LOG_WRN("Next write_default() call will succeed");
	LOG_WRN("Lock will auto-reset after write");
	default_write_unlocked = true;
	
	return 0;
}

bool config_storage_is_default_write_enabled(void)
{
#ifdef CONFIG_CONFIG_ALLOW_DEFAULT_WRITE
	return default_write_unlocked;
#else
	return false;
#endif
}

int config_storage_erase_all(void)
{
	if (!initialized) {
		LOG_ERR("Cannot erase: not initialized");
		return -EACCES;
	}
	
	LOG_WRN("*** ERASING ALL CONFIGURATION STORAGE ***");
	LOG_WRN("This will erase DEFAULT, AREA_A, and AREA_B");
	
	/* Erase both areas */
	int ret;
	
	LOG_INF("Erasing AREA_A at 0x%08x...", CONFIG_AREA_A_OFFSET);
	ret = flash_erase(flash_dev, CONFIG_AREA_A_OFFSET, FLASH_PAGE_SIZE);
	if (ret != 0) {
		LOG_ERR("Failed to erase AREA_A: %d", ret);
		return ret;
	}
	
	LOG_INF("Erasing AREA_B at 0x%08x...", CONFIG_AREA_B_OFFSET);
	ret = flash_erase(flash_dev, CONFIG_AREA_B_OFFSET, FLASH_PAGE_SIZE);
	if (ret != 0) {
		LOG_ERR("Failed to erase AREA_B: %d", ret);
		return ret;
	}
	
	LOG_WRN("All configuration areas erased - device will use defaults on next boot");
	LOG_WRN("*** REBOOT REQUIRED ***");
	
	return 0;
}
```

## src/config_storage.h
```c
/*
 * Copyright (c) 2026 GuitarAcc Project
 * SPDX-License-Identifier: Apache-2.0
 */

#ifndef CONFIG_STORAGE_H_
#define CONFIG_STORAGE_H_

#include <zephyr/kernel.h>
#include <stdint.h>
#include "accel_mapping.h"

/**
 * @brief Configuration Storage Module
 * 
 * This module manages configuration data in external QSPI flash using a 
 * redundant storage scheme with three areas:
 * 
 * - DEFAULT: Factory default configuration (read-only after initial write)
 * - AREA_A: Primary active storage area
 * - AREA_B: Secondary active storage area (ping-pong with A)
 * 
 * The system ping-pongs between A and B, always using the most recent valid
 * configuration (determined by sequence number and hash validation).
 */

/* Configuration data structure version */
#define CONFIG_VERSION 1

/* Maximum configuration data size (excluding header) */
#define CONFIG_DATA_MAX_SIZE 4096

/* SHA256 hash size */
#define CONFIG_HASH_SIZE 32

/**
 * @brief Configuration header structure
 * 
 * Stored at the beginning of each configuration area to track version,
 * sequence number, and hash for validation.
 */
struct config_header {
	uint32_t magic;           /* Magic number: 0x47544143 ("GTAC") */
	uint32_t version;         /* Configuration structure version */
	uint32_t sequence;        /* Sequence number for ping-pong selection */
	uint32_t data_size;       /* Size of configuration data */
	uint8_t  hash[CONFIG_HASH_SIZE]; /* SHA256 hash of data */
	uint32_t crc32;           /* CRC32 of header (excluding this field) */
} __packed;

/**
 * @brief Global configuration structure
 * 
 * System-level settings that apply across all patches.
 * These settings are typically hardware or user preference related.
 */
struct global_config {
	/* Patch management */
	uint8_t default_patch;         /* Active patch index (0-126) */
	
	/* MIDI configuration */
	uint8_t midi_channel;          /* MIDI channel (0-15) */
	
	/* BLE configuration */
	uint8_t max_guitars;           /* Maximum connected guitars (1-4) */
	uint8_t scan_interval_ms;      /* BLE scan interval */
	
	/* LED configuration */
	uint8_t led_brightness;        /* LED brightness (0-255) */
	
	/* Accelerometer mapping */
	int16_t accel_scale[6];        /* Full-scale G-force in milli-g (100-4000mg) that maps to MIDI 0-127 */
	int16_t accel_offset[6];       /* Center point offset in milli-g (e.g., 200mg makes +200mg → MIDI 64) */
	
	/* Filter configuration */
	uint8_t running_average_enable; /* Enable running average filter (0/1) */
	uint8_t running_average_depth;  /* Running average depth (3-10) */
	
	/* Reserved for future global settings */
	uint8_t reserved[21];          /* Future expansion (21 bytes for 4-byte alignment) */
} __packed;

/**
 * @brief Patch configuration structure
 * 
 * Patch-specific settings that can vary between different
 * performances, songs, or sound designs.
 */
struct patch_config {
	/* MIDI mapping configuration */
	uint8_t velocity_curve;        /* Velocity curve type (0-3) */
	uint8_t cc_mapping[6];         /* CC numbers for 6 axes */
	
	/* LED configuration */
	uint8_t led_mode;              /* LED mode (0-3) */
	
	/* Accelerometer mapping */
	int16_t accel_deadzone;        /* Deadzone threshold */
	uint8_t accel_min[6];          /* Minimum CC value for each axis (0-127) */
	uint8_t accel_max[6];          /* Maximum CC value for each axis (0-127) */
	uint8_t accel_invert;          /* Inversion bitfield: bit 0-5 for axes 0-5 */
	
	/* Patch metadata */
	char patch_name[32];           /* Patch name (null-terminated) */
	
	/* Accelerometer rotation pipeline */
	struct accel_rotation_config rotation_pipeline; /* 3D rotation and conversion pipeline (15 bytes) */
	
	/* Reserved for future patch settings */
	uint8_t reserved[38];          /* Future expansion (38 bytes: 53 - 15) */
} __packed;

/**
 * @brief Combined configuration data structure
 * 
 * Contains both global and patch-specific settings.
 * This structure is stored in flash and survives power cycles.
 * 
 * NOTE: Supports up to 16 patches. The active patch is selected
 * via global.default_patch index.
 */
struct config_data {
	struct global_config global;   /* Global system settings */
	struct patch_config patches[16]; /* Array of 16 patches */
	
	/* Reserved for future use */
	uint8_t reserved[32];          /* Additional expansion space */
} __packed;

/* Compile-time assertion: nRF5340 flash requires 4-byte aligned writes */
BUILD_ASSERT(sizeof(struct config_data) % 4 == 0, 
	     "config_data size must be 4-byte aligned for flash writes");

/**
 * @brief Storage area identifiers
 */
enum config_area {
	CONFIG_AREA_A = 0,        /* Active storage A */
	CONFIG_AREA_B = 1,        /* Active storage B */
};

/**
 * @brief Initialize configuration storage system
 * 
 * Initializes QSPI flash driver, validates all storage areas, and loads
 * the most recent valid configuration. If no valid configuration exists,
 * loads from DEFAULT area. If DEFAULT is invalid, uses hardcoded defaults.
 * 
 * @return 0 on success, negative errno on failure
 */
int config_storage_init(void);

/**
 * @brief Save configuration data
 * 
 * Writes configuration to the inactive area (ping-pong), increments sequence
 * number, calculates hash, and updates header. The new area becomes active.
 * 
 * @param data Pointer to configuration data structure
 * @return 0 on success, negative errno on failure
 */
int config_storage_save(const struct config_data *data);

/**
 * @brief Load current configuration data
 * 
 * Retrieves the currently active configuration (most recent valid area).
 * 
 * @param data Pointer to buffer for configuration data
 * @return 0 on success, negative errno on failure
 */
int config_storage_load(struct config_data *data);

/**
 * @brief Restore factory default configuration
 * 
 * Loads hardcoded default configuration and saves it to active storage.
 * 
 * @return 0 on success, negative errno on failure
 */
int config_storage_restore_defaults(void);

/**
 * @brief Erase all configuration storage areas (testing only)
 * 
 * Returns information about sequence numbers, active area, and validation
 * status for debugging purposes.
 * 
 * @param active_area Pointer to store active area identifier
 * @param sequence Pointer to store current sequence number
 * @return 0 on success, negative errno on failure
 */
int config_storage_get_info(enum config_area *active_area, uint32_t *sequence);

/**
 * @brief Erase all configuration storage areas (testing only)
 * 
 * Erases DEFAULT, AREA_A, and AREA_B to simulate a brand new device.
 * Used for testing initialization with no stored configuration.
 * 
 * WARNING: This permanently erases all stored configuration!
 * Only use for testing and development.
 * 
 * @return 0 on success, negative errno on failure
 */
int config_storage_erase_all(void);

/**
 * @brief Get default configuration values (hardcoded)
 * 
 * Returns hardcoded default configuration used when no valid stored
 * configuration exists.
 * 
 * @param data Pointer to buffer for default configuration
 */
void config_storage_get_hardcoded_defaults(struct config_data *data);

#endif /* CONFIG_STORAGE_H_ */
```

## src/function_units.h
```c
/*
 * Function Units
 * Signal processing blocks for virtual port system
 * 
 * Copyright (c) 2026 GuitarAcc Project
 * SPDX-License-Identifier: Apache-2.0
 */

#ifndef FUNCTION_UNITS_H
#define FUNCTION_UNITS_H

#include <stdint.h>
#include <stdbool.h>

/* ========================================
 * CONSTANTS
 * ======================================== */

#define FUNC_MAX_PARAMS     6    /* Maximum parameters per function */

/* ========================================
 * FUNCTION TYPES
 * ======================================== */

/**
 * @brief Function unit types
 * 
 * Each type performs a different signal processing operation.
 */
enum function_type {
	FUNC_DISABLED = 0,      /* Function unit not active */
	FUNC_PASSTHROUGH,       /* Direct copy (output = input) */
	FUNC_LINEAR,            /* Linear scaling with configurable range */
	FUNC_SCALE_OFFSET,      /* Global scale/offset calibration (reads from global config) */
	FUNC_DEADZONE,          /* Zero output below threshold */
	FUNC_INVERT,            /* Invert signal (127 - input) */
	FUNC_SCALE,             /* Multiply and clamp */
	FUNC_CLAMP,             /* Clamp to min/max range */
	/* Future function types */
	FUNC_CURVE_EXP,         /* Exponential curve */
	FUNC_CURVE_LOG,         /* Logarithmic curve */
	FUNC_LOWPASS,           /* Low-pass filter */
};

/* ========================================
 * DATA STRUCTURES
 * ======================================== */

/**
 * @brief Function unit configuration
 * 
 * Stores function type and parameters. Parameters are interpreted
 * differently based on function type.
 */
struct function_unit {
	uint8_t function_type;      /* enum function_type */
	uint8_t enabled;            /* Active flag */
	uint8_t param_count;        /* Number of valid parameters */
	uint8_t reserved;           /* Padding */
	int16_t params[FUNC_MAX_PARAMS]; /* Type-specific parameters */
} __attribute__((packed));

/* ========================================
 * PARAMETER DEFINITIONS BY FUNCTION TYPE
 * ======================================== */

/*
 * FUNC_PASSTHROUGH: No parameters
 *   output = input
 *
 * FUNC_LINEAR: params[0]=input_min, params[1]=input_max, 
 *              params[2]=output_min, params[3]=output_max
 *   Maps input range [input_min, input_max] to output range [output_min, output_max]
 *   Example: params={-2000, 2000, 0, 127} maps ±2g to full MIDI range
 *
 * FUNC_SCALE_OFFSET: params[0]=sensor_index (0-5)
 *   Applies global scale and offset calibration from config.global.accel_scale[] 
 *   and config.global.accel_offset[]. This is a shared calibration resource.
 *   Formula: output = ((input - offset) * 127) / scale
 *   Example: params={0} applies calibration for sensor 0 (Accel X)
 *   Note: Requires access to global configuration structure
 *
 * FUNC_DEADZONE: params[0]=threshold
 *   output = (abs(input) < threshold) ? 0 : input
 *   Example: params={10} zeros out small noise below ±10
 *
 * FUNC_INVERT: No parameters
 *   output = 127 - input
 *
 * FUNC_SCALE: params[0]=scale_factor (fixed point, divide by 100)
 *   output = (input * scale_factor) / 100, clamped to 0-127
 *   Example: params={150} multiplies by 1.5x
 *
 * FUNC_CLAMP: params[0]=min, params[1]=max
 *   output = clamp(input, min, max)
 */

/* ========================================
 * API FUNCTIONS
 * ======================================== */

/**
 * @brief Initialize a function unit with defaults
 * 
 * @param func Pointer to function unit
 * @param type Function type to configure
 */
void func_init(struct function_unit *func, enum function_type type);

/**
 * @brief Initialize a linear function unit
 * 
 * Convenience function for the common linear mapping case.
 * 
 * @param func Pointer to function unit
 * @param input_min Minimum input value
 * @param input_max Maximum input value
 * @param output_min Minimum output value (typically 0)
 * @param output_max Maximum output value (typically 127)
 */
void func_init_linear(struct function_unit *func, 
                      int16_t input_min, int16_t input_max,
                      int16_t output_min, int16_t output_max);

/**
 * @brief Initialize a scale/offset function unit
 * 
 * This function type applies global calibration from config.global.
 * 
 * @param func Pointer to function unit
 * @param sensor_index Sensor index (0-5) to calibrate
 */
void func_init_scale_offset(struct function_unit *func, uint8_t sensor_index);

/**
 * @brief Initialize a deadzone function unit
 * 
 * @param func Pointer to function unit
 * @param threshold Deadzone threshold (abs value)
 */
void func_init_deadzone(struct function_unit *func, int16_t threshold);

/**
 * @brief Process an input value through a function unit
 * 
 * Applies the function transformation to the input value.
 * 
 * @param func Pointer to function unit
 * @param input Input value
 * @return Processed output value
 */
int16_t func_process(const struct function_unit *func, int16_t input);

/**
 * @brief Validate function unit configuration
 * 
 * @param func Pointer to function unit
 * @return true if valid, false otherwise
 */
bool func_validate(const struct function_unit *func);

/**
 * @brief Get a human-readable name for a function type
 * 
 * @param type Function type enum value
 * @return String name, or "Unknown" for invalid types
 */
const char *func_get_name(enum function_type type);

#endif /* FUNCTION_UNITS_H */
```
